# MKW38A4 register map
Vendor: NXP Semiconductors; Series: Kinetis_W; File version: 1.6
CPU: CM0PLUS r0p0, little endian, no MPU, no FPU, VTOR, 2 interrupt priority bits
Registers are 32-bit, read-write, no defined reset value unless marked. A register's access mark holds for its fields unless they carry their own. Offsets are from the block's base; [hi:lo] are bit positions; 'fields as' and 'values as' point back to an identical list.

## RSIM
Base 0x40059000
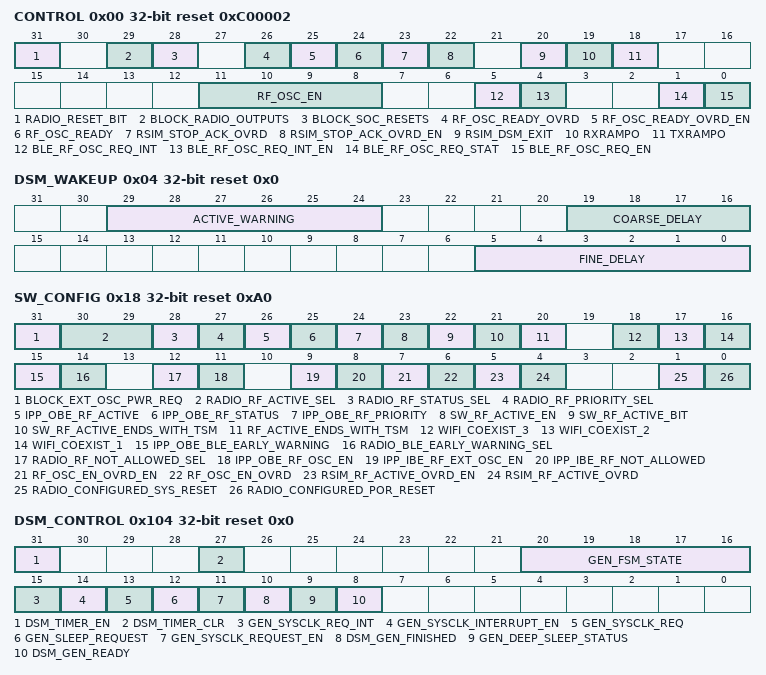
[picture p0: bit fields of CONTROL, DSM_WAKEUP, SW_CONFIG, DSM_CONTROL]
0x00 CONTROL reset 0xC00002 — Radio System Control
  [31] RADIO_RESET_BIT — Software Reset for the Radio
  [29] BLOCK_RADIO_OUTPUTS
  [28] BLOCK_SOC_RESETS — Block SoC Resets of the Radio
  [26] RF_OSC_READY_OVRD — RF Ref Osc Ready Override
  [25] RF_OSC_READY_OVRD_EN — RF Ref Osc Ready Override Enable
  [24] RF_OSC_READY ro — RF Ref Osc Ready
  [23] RSIM_STOP_ACK_OVRD — Stop Acknowledge Override
  [22] RSIM_STOP_ACK_OVRD_EN — Stop Acknowledge Override Enable
  [20] RSIM_DSM_EXIT — Bluetooth LE Force Deep Sleep Mode Exit
  [19] RXRAMPO — Radio RX RAM Power Option
    0=RX RAM not powered in VLLS2; 1=RX RAM powered in VLLS2
  [18] TXRAMPO — Radio TX RAM Power Option
    0=TX RAM not powered in VLLS2; 1=TX RAM powered in VLLS2
  [11:8] RF_OSC_EN — RF Ref Osc Enable Select
    0=RF Ref Osc is controlled by the SoC, external pin, or a link layer; 1=RF Ref Osc on in Run/Wait; 3=RF Ref Osc on in Stop; 7=RF Ref Osc on in VLPR/VLPW; 15=RF Ref Osc on in VLPS
  [5] BLE_RF_OSC_REQ_INT — Bluetooth LE Ref Osc (Sysclk) Request Interrupt Flag
  [4] BLE_RF_OSC_REQ_INT_EN — Bluetooth LE Ref Osc (Sysclk) Request Interrupt Enable
  [1] BLE_RF_OSC_REQ_STAT ro — Bluetooth LE Ref Osc (Sysclk) Request Status
  [0] BLE_RF_OSC_REQ_EN — Bluetooth LE Ref Osc (Sysclk) Request Enable
0x04 DSM_WAKEUP reset 0x0 — Deep Sleep Wake-up Sequence
  [29:24] ACTIVE_WARNING — Deep Sleep Wake-up RF Active Warning Time
  [19:16] COARSE_DELAY — Deep Sleep Wake-up Coarse Delay Time
  [5:0] FINE_DELAY — Deep Sleep Wake-up Fine Delay Time
0x08 MAC_MSB ro reset 0x0 — Radio MAC Address
  [7:0] MAC_ADDR_MSB — Radio MAC Address MSB
0x0C MAC_LSB ro reset 0x0 — Radio MAC Address
  [31:0] MAC_ADDR_LSB — Radio MAC Address LSB
0x10 MISC reset 0x6000000 — Radio Miscellaneous
  [31:24] RADIO_VERSION — Radio Version ID number
0x18 SW_CONFIG reset 0xA0 — Radio Software Configuration
  [31] BLOCK_EXT_OSC_PWR_REQ — Block External Requests for RF Ref OSC from starting a Radio Power Wake-up Sequence
  [30:29] RADIO_RF_ACTIVE_SEL — Radio RF_ACTIVE Select
    0=PTC4; 1=PTB3; 2=PTA0
  [28] RADIO_RF_STATUS_SEL — Radio RF_STATUS Select
    0=PTC16; 1=PTA1
  [27] RADIO_RF_PRIORITY_SEL — Radio RF_PRIORITY Select
    0=PTB1; 1=PTC5
  [26] IPP_OBE_RF_ACTIVE
  [25] IPP_OBE_RF_STATUS
  [24] IPP_OBE_RF_PRIORITY
  [23] SW_RF_ACTIVE_EN — Software RF_ACTIVE Control Enable
  [22] SW_RF_ACTIVE_BIT — Software RF_ACTIVE Control Bit
  [21] SW_RF_ACTIVE_ENDS_WITH_TSM — Software RF_ACTIVE clearing mechanism
  [20] RF_ACTIVE_ENDS_WITH_TSM — RF_ACTIVE clearing mechanism
  [18] WIFI_COEXIST_3 — RF_EARLY_WARNING Source
  [17] WIFI_COEXIST_2 — RF_STATUS Source
  [16] WIFI_COEXIST_1 — RF_ACTIVE Source
  [15] IPP_OBE_BLE_EARLY_WARNING
  [14] RADIO_BLE_EARLY_WARNING_SEL — Radio BLE_EARLY_WARNING Select
    0=PTC19; 1=PTC1
  [12] RADIO_RF_NOT_ALLOWED_SEL — Radio RF_NOT_ALLOWED Select
    0=PTB2; 1=PTC5
  [11] IPP_OBE_RF_OSC_EN
  [9] IPP_IBE_RF_EXT_OSC_EN
  [8] IPP_IBE_RF_NOT_ALLOWED
  [7] RF_OSC_EN_OVRD_EN — Radio Osc Enable Override Enable
  [6] RF_OSC_EN_OVRD — Radio Osc Enable Override
  [5] RSIM_RF_ACTIVE_OVRD_EN — RF Active Internal Override Enable
  [4] RSIM_RF_ACTIVE_OVRD — RF Active Internal Override
  [1] RADIO_CONFIGURED_SYS_RESET — Radio Configuration Bit, cleared by Radio System Reset
  [0] RADIO_CONFIGURED_POR_RESET — Radio Configuration Bit, cleared by Radio power-on reset
0x100 DSM_TIMER ro reset 0x0 — Deep Sleep Timer
  [23:0] DSM_TIMER — Deep Sleep Mode Timer
0x104 DSM_CONTROL reset 0x0 — Deep Sleep Timer Control
  [31] DSM_TIMER_EN — Deep Sleep Mode Timer Enable
  [27] DSM_TIMER_CLR — Deep Sleep Mode Timer Clear
  [20:16] GEN_FSM_STATE ro — GEN Deep Sleep State Machine State
  [15] GEN_SYSCLK_REQ_INT — Interrupt Flag from an Generic FSK Link Layer RF Ref OSC Request
  [14] GEN_SYSCLK_INTERRUPT_EN — Generic FSK Link Layer RF Ref OSC Request Interrupt Enable
  [13] GEN_SYSCLK_REQ ro — Generic FSK Link Layer RF Ref OSC Request Status
  [12] GEN_SLEEP_REQUEST ro — Generic FSK Link Layer Deep Sleep Requested
  [11] GEN_SYSCLK_REQUEST_EN — Enable Generic FSK Link Layer to Request RF Ref OSC
  [10] DSM_GEN_FINISHED ro — Generic FSK Deep Sleep Time Finished
  [9] GEN_DEEP_SLEEP_STATUS ro — Generic FSK Link Layer Deep Sleep Mode Status
  [8] DSM_GEN_READY ro — Generic FSK Ready for Deep Sleep Mode
0x108 DSM_OSC_OFFSET reset 0x0 — Deep Sleep Wake-up Time Offset
  [9:0] DSM_OSC_STABILIZE_TIME — Deep Sleep Wake-up RF Ref OSC Stabilize Time
0x11C GEN_SLEEP reset 0x0 — Generic FSK Link Layer Sleep Time
  [23:0] GEN_SLEEP_TIME
0x120 GEN_WAKE reset 0x0 — Generic FSK Link Layer Wake Time
  [23:0] GEN_WAKE_TIME
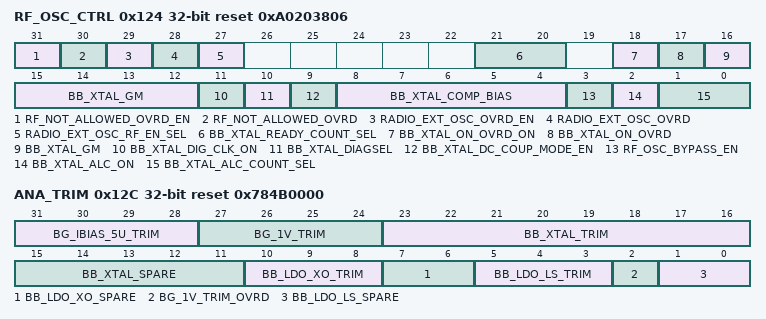
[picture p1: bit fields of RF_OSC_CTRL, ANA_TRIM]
0x124 RF_OSC_CTRL reset 0xA0203806 — Radio Oscillator Control
  [31] RF_NOT_ALLOWED_OVRD_EN — RF Not Allowed Override Enable
  [30] RF_NOT_ALLOWED_OVRD — RF Not Allowed Override
  [29] RADIO_EXT_OSC_OVRD_EN — Radio External Request for RF Ref OSC Override Enable
  [28] RADIO_EXT_OSC_OVRD — Radio External Request for RF Ref OSC Override
  [27] RADIO_EXT_OSC_RF_EN_SEL — Radio External Request for RF Ref OSC Select
    0=PTC6; 1=PTB0
  [21:20] BB_XTAL_READY_COUNT_SEL — rmap_bb_xtal_ready_count_sel_hv[1:0]
    0=1024 counts (32 us @ 32 MHz); 1=2048 (64 us @ 32 MHz); 2=4096 (128 us @ 32 MHz); 3=8192 (256 us @ 32 MHz)
  [18] BB_XTAL_ON_OVRD_ON — rmap_bb_xtal_on_ovrd_on_hv
    0=rfctrl_bb_xtal_on_hv is asserted; 1=rfctrl_bb_xtal_on_ovrd_hv is asserted
  [17] BB_XTAL_ON_OVRD — rmap_bb_xtal_on_ovrd_hv
  [16:12] BB_XTAL_GM — rmap_bb_xtal_gm_hv[4:0]
  [11] BB_XTAL_DIG_CLK_ON — rmap_bb_xtal_dig_clk_on_hv
  [10] BB_XTAL_DIAGSEL — rmap_bb_xtal_diagsel_hv
  [9] BB_XTAL_DC_COUP_MODE_EN — rmap_bb_xtal_dc_coup_mode_en_hv
  [8:4] BB_XTAL_COMP_BIAS — rmap_bb_xtal_comp_bias_hv[4:0]
  [3] RF_OSC_BYPASS_EN — RF Ref Osc Bypass Enable
  [2] BB_XTAL_ALC_ON — rmap_bb_xtal_alc_on_hv
  [1:0] BB_XTAL_ALC_COUNT_SEL — rmap_bb_xtal_alc_count_sel_hv[1:0]
    0=2048 (64 us @ 32 MHz); 1=4096 (128 us @ 32 MHz); 2=8192 (256 us @ 32 MHz); 3=16384 (512 us @ 32 MHz)
0x128 ANA_TEST reset 0x0 — Radio Analog Test Registers
  [4] XTAL_OUT_BUF_EN — XTAL Output Buffer Enable
0x12C ANA_TRIM reset 0x784B0000 — Radio Analog Trim Registers
  [31:28] BG_IBIAS_5U_TRIM — rmap_bg_ibias_5u_trim_hv[3:0]
    0=3.55 uA; 1=3.73 uA; 2=4.04 uA; 3=4.22 uA; 4=4.39 uA; 5=4.57 uA; 6=4.89 uA; 7=5.06 (Default); 8=5.23 uA; 9=5.41 uA; 10=5.72 uA; 11=5.9 uA; 12=6.07 uA; 13=6.25 uA; 14=6.56 uA; 15=6.74 uA
  [27:24] BG_1V_TRIM — rmap_bg_1v_trim_hv[3:0]
    0=954.14 mV; 1=959.26 mV; 2=964.38 mV; 3=969.5 mV; 4=974.6 mV; 5=979.7 mV; 6=984.8 mV; 7=989.9 mV; 8=995 mV (Default); 9=1 V; 10=1.005 V; 11=1.01 V; 12=1.015 V; 13=1.02 V; 14=1.025 V; 15=1.031 V
  [23:16] BB_XTAL_TRIM — rmap_bb_xtal_trim_hv[7:0]
  [15:11] BB_XTAL_SPARE — rmap_bb_xtal_spare_hv[4:0]
  [10:8] BB_LDO_XO_TRIM — rmap_bb_ldo_xo_trim_hv[2:0]
    0=1.20 V (Default); 1=1.25 V; 2=1.28 V; 3=1.33 V; 4=1.40 V; 5=1.44 V; 6=1.50 V; 7=1.66 V
  [7:6] BB_LDO_XO_SPARE — rmap_bb_ldo_xo_spare_hv[1:0]
  [5:3] BB_LDO_LS_TRIM — rmap_bb_ldo_ls_trim_hv[2:0]
    values as BB_LDO_XO_TRIM
  [2] BG_1V_TRIM_OVRD — Bandgap 1V Trim Override
  [1:0] BB_LDO_LS_SPARE — rmap_bb_ldo_ls_spare_hv[1:0]
